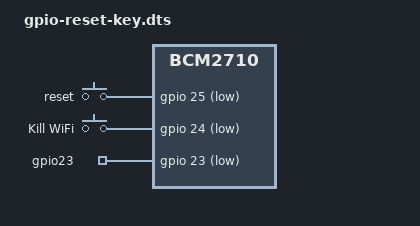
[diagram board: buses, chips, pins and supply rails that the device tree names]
// Definitions for rpi-gpio-pins
/dts-v1/;
/plugin/;

// This overlay sets up an input device that generates KEY_RESTART events
// when a given GPIO pin changes. It defaults to using GPIO25, which can
// also be used to wake up (start) the Rpi again after shutdown. Since
// wakeup is active-low, this defaults to active-low with a pullup
// enabled, but all of this can be changed using overlay parameters (but
// note that GPIO3 has an external pullup on at least some boards).

/ {
	compatible = "brcm,bcm2835", "brcm,bcm2708", "brcm,bcm2709", "brcm,bcm2710";

	fragment@0 {
		// Configure the gpio pin controller
		target = <&gpio>;
		__overlay__ {
			// Define a pinctrl state, that sets up the gpio
			// as an input with a pullup enabled. This does
			// not take effect by itself, only when referenced
			// by a "pinctrl client", as is done below. See:
			//   https://www.kernel.org/doc/Documentation/devicetree/bindings/pinctrl/pinctrl-bindings.txt
			//   https://www.kernel.org/doc/Documentation/devicetree/bindings/pinctrl/brcm,bcm2835-gpio.txt
			rpi_gpio_pins: rpi_gpio_pins {
				brcm,pins = <23 24 25>; // gpio number
				brcm,function = <0 0 0>; // 0 = input, 1 = output
				brcm,pull = <2 2 2>; // 0 = none, 1 = pull down, 2 = pull up
			};
		};
	};
	fragment@1 {
		// Add a new device to the / devicetree node
		target-path = "/";
		__overlay__ {
			gpio-keys-polled {
				compatible = "gpio-keys-polled";
				poll-interval = <20>;

				// Declare a single pinctrl state (referencing the one declared above) and name it
				// default, so it is activated automatically.
				pinctrl-names = "default";
				pinctrl-0 = <&rpi_gpio_pins>;

				// Enable this device
				status = "okay";

				reset {
					label = "reset";
					gpios = <&gpio 25 1>;
					linux,code = <0x198>;
				};

				rfkill {
					label = "Kill WiFi";
					gpios = <&gpio 24 1>;
				};

				gpio23 {
					label = "gpio23";
					gpios = <&gpio 23 1>;
				};
			};
		};
	};
};
